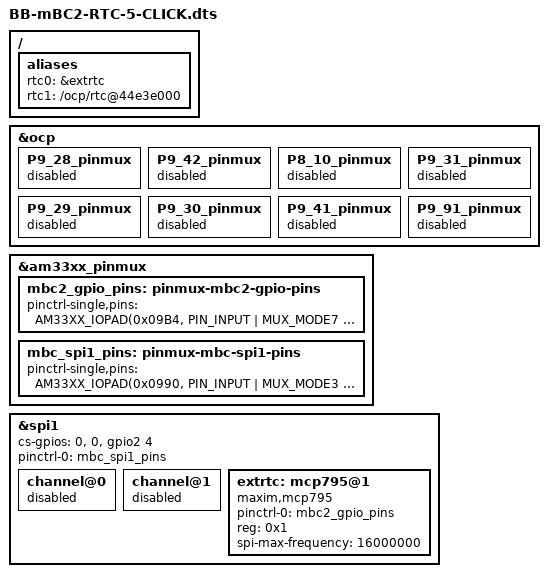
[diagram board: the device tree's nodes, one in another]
/*
 * Copyright (C) 2018 Robert Nelson <robertcnelson@gmail.com>
 *
 * This program is free software; you can redistribute it and/or modify
 * it under the terms of the GNU General Public License version 2 as
 * published by the Free Software Foundation.
 *
 * https://www.mikroe.com/rtc-5-click
 * https://download.mikroe.com/documents/add-on-boards/click/rtc-5/rtc-5-click-manual-v100.pdf
 */

/dts-v1/;
/plugin/;

#include <dt-bindings/gpio/gpio.h>
#include <dt-bindings/pinctrl/am33xx.h>
#include <dt-bindings/interrupt-controller/irq.h>

/ {
	/*
	 * Free up the pins used by the cape from the pinmux helpers.
	 */
	fragment@0 {
		target = <&ocp>;
		__overlay__ {
			//P9_23_pinmux { status = "disabled"; };	/* RESET - gpio1[17] */

			/* Click 1 */
			P9_28_pinmux { status = "disabled"; };	/* CS - spi1_cs0 */

			/* Click 2 */
			P9_42_pinmux { status = "disabled"; };	/* CS - spi1_cs1 */

			/* Click 4 */
			P8_10_pinmux { status = "disabled"; };  /* CS - gpmc_wen.gpio2_4 */

			P9_31_pinmux { status = "disabled"; };	/* SCK - spi1_sclk */
			P9_29_pinmux { status = "disabled"; };	/* MISO - spi1_d0 */
			P9_30_pinmux { status = "disabled"; };	/* MOSI - spi1_d1 */

			// P9_16_pinmux { status = "disabled"; };	/* PWM - ehrpwm1b */
			P9_41_pinmux { status = "disabled"; };	/* MFP - gpio0[20] */
			P9_91_pinmux { status = "disabled"; };	/* Shared with P9_41 */
			//P9_26_pinmux { status = "disabled"; };	/* RX - uart1_rxd */
			//P9_24_pinmux { status = "disabled"; };	/* TX - uart1_txd */
			//P9_19_pinmux { status = "disabled"; };	/* SCL */
			//P9_20_pinmux { status = "disabled"; };	/* SDA */
		};
	};

	fragment@1 {
		target-path="/";
		__overlay__ {
			aliases {
				rtc0 = &extrtc;
				rtc1 = "/ocp/rtc@44e3e000";
			};
		};
	};

	fragment@2 {
		target = <&am33xx_pinmux>;
		__overlay__ {
			mbc2_gpio_pins: pinmux-mbc2-gpio-pins {
				pinctrl-single,pins = <
					AM33XX_IOPAD(0x09B4, PIN_INPUT | MUX_MODE7 ) /* P9_41 (D14) xdma_event_intr1.gpio0[20] MFP */
					AM33XX_IOPAD(0x09A8, PIN_INPUT | MUX_MODE7 ) /* P9_91 Shared with P9_41 mcasp0_axr1.gpio3_20 */
					//AM33XX_IOPAD(0x0844, PIN_INPUT | MUX_MODE7 ) /* P9_23 (V14) gpmc_a1.gpio1[17] RESET */
				>;
			};

			mbc_spi1_pins: pinmux-mbc-spi1-pins {
				pinctrl-single,pins = <
					AM33XX_IOPAD(0x0990, PIN_INPUT | MUX_MODE3 ) /* P9_31 (A13) mcasp0_aclkx.spi1_sclk */
					AM33XX_IOPAD(0x0994, PIN_INPUT | MUX_MODE3 ) /* P9_29 (B13) mcasp0_fsx.spi1_d0 */
					AM33XX_IOPAD(0x0998, PIN_INPUT | MUX_MODE3 ) /* P9_30 (D12) mcasp0_axr0.spi1_d1 */

					/* Click 1 */
					AM33XX_IOPAD(0x099C, PIN_INPUT | MUX_MODE3 ) /* P9_28 (C12) mcasp0_ahclkr.spi1_cs0 */
					/* Click 2 */
					AM33XX_IOPAD(0x0964, PIN_INPUT | MUX_MODE2 ) /* P9_42 (C18) eCAP0_in_PWM0_out.spi1_cs1 */
					/* Click 4 */
					AM33XX_IOPAD(0x0898, PIN_INPUT | MUX_MODE7 ) /* P8_10 (U6) gpmc_wen.gpio2_4 */
				>;
			};
		};
	};

	fragment@3 {
		target = <&spi1>;
		__overlay__ {
			status = "okay";
			cs-gpios = <0>, <0>, <&gpio2 4 GPIO_ACTIVE_HIGH>;
			pinctrl-names = "default";
			pinctrl-0 = <&mbc_spi1_pins>;

			channel@0{ status = "disabled"; };
			channel@1{ status = "disabled"; };
		};
	};

	fragment@4 {
		target = <&spi1>;
		__overlay__ {
			#address-cells = <1>;
			#size-cells = <0>;

			extrtc: mcp795@1 {
				compatible = "maxim,mcp795";
				pinctrl-names = "default";
				pinctrl-0 = <&mbc2_gpio_pins>;
				reg = <0x1>;
				spi-max-frequency = <16000000>;
			};
		};
	};
};
